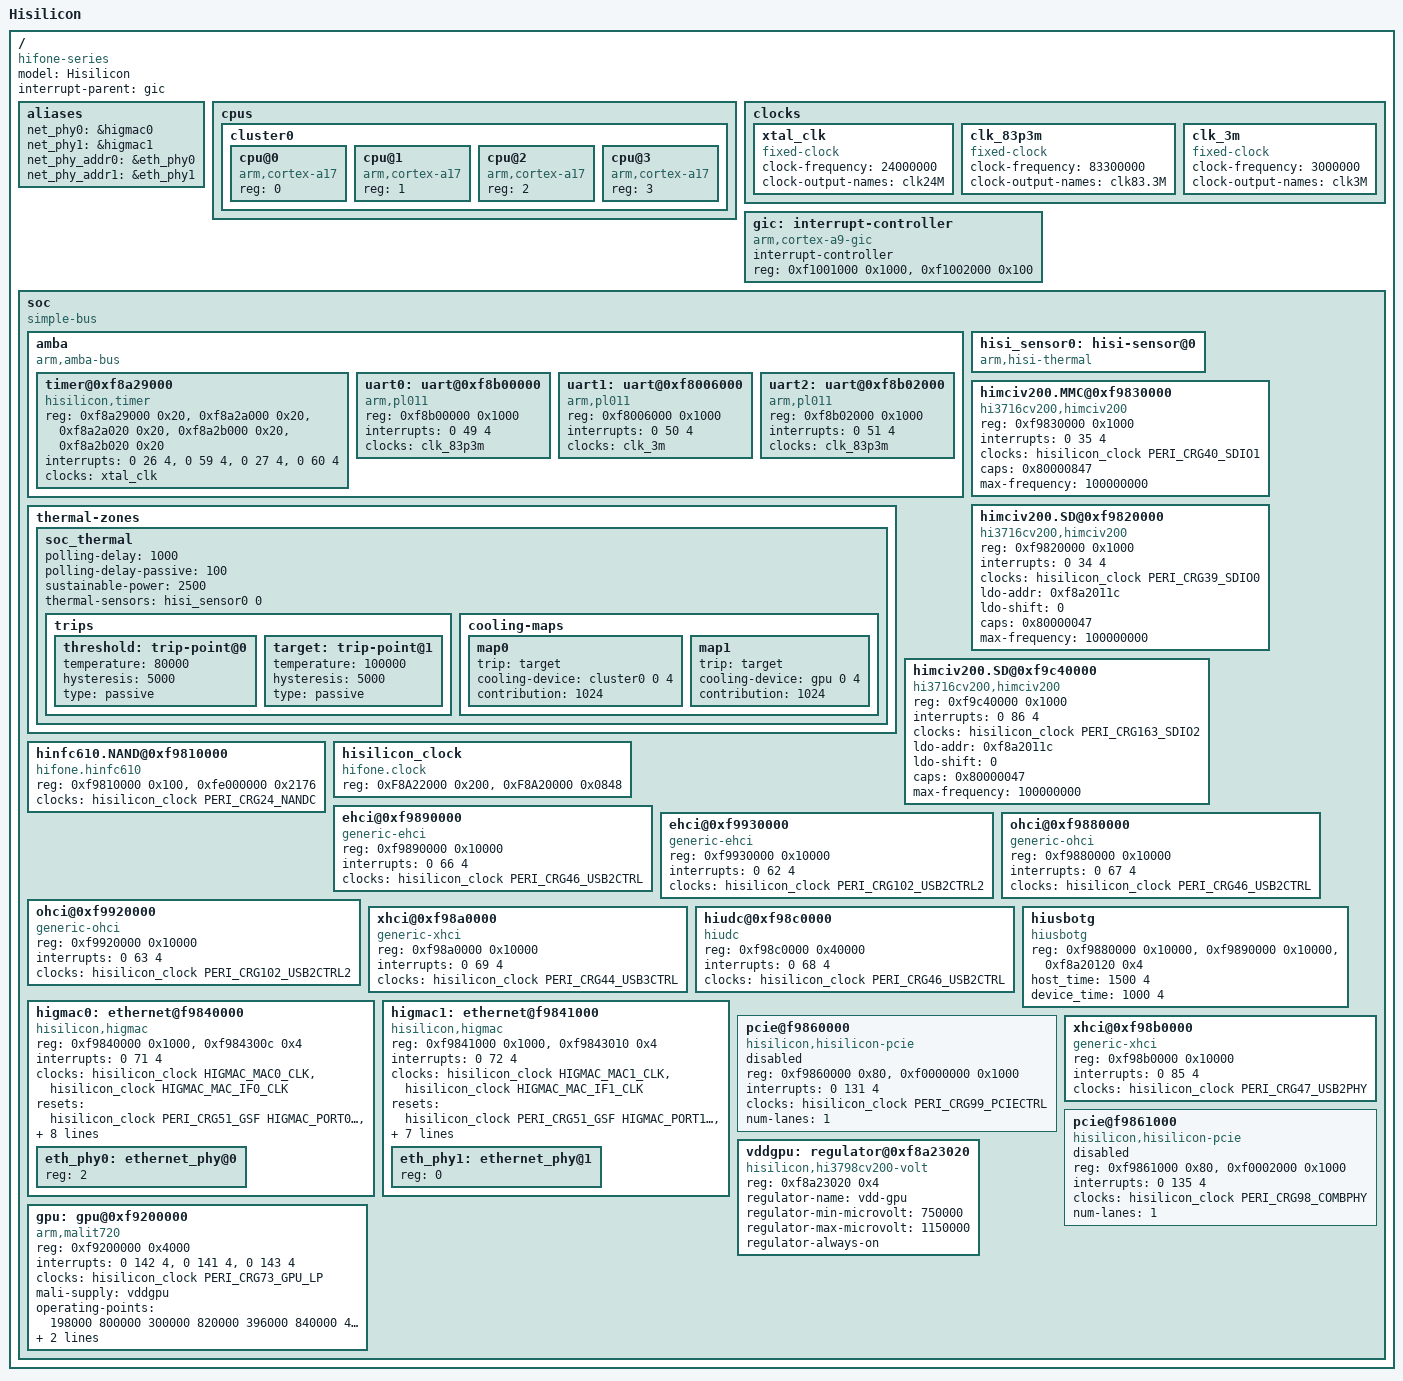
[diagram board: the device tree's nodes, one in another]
/dts-v1/;

#include <dt-bindings/clock/hifone-clock.h>

/ {
	model = "Hisilicon";
	compatible = "hifone-series";
	#address-cells = <1>;
	#size-cells = <1>;
	interrupt-parent = <&gic>;

	aliases {
		net_phy0 = &higmac0;
		net_phy1 = &higmac1;
		net_phy_addr0 = &eth_phy0;
		net_phy_addr1 = &eth_phy1;
	};

	cpus {
		cluster0: cluster0 {
			#address-cells = <1>;
			#size-cells = <0>;

			/* cooling options */
			#cooling-cells = <2>; /* min followed by max */

			cpu@0 {
				device_type = "cpu";
				compatible = "arm,cortex-a17";
				reg = <0>;
			};

			cpu@1 {
				device_type = "cpu";
				compatible = "arm,cortex-a17";
				reg = <1>;
			};

			cpu@2 {
				device_type = "cpu";
				compatible = "arm,cortex-a17";
				reg = <2>;
			};

			cpu@3 {
				device_type = "cpu";
				compatible = "arm,cortex-a17";
				reg = <3>;
			};
		}; /* cluster0 */
	}; /* cpus */

	clocks {
		xtal_clk: xtal_clk {
			compatible = "fixed-clock";
			#clock-cells = <0>;
			clock-frequency = <24000000>;
			clock-output-names = "clk24M";
		};

		clk_83p3m: clk_83p3m {
			compatible = "fixed-clock";
			#clock-cells = <0>;
			clock-frequency = <83300000>;
			clock-output-names = "clk83.3M";
		};

		clk_3m: clk_3m{
			compatible = "fixed-clock";
			#clock-cells = <0>;
			clock-frequency = <3000000>;
			clock-output-names = "clk3M";
		};
	};

	gic: interrupt-controller {
		compatible = "arm,cortex-a9-gic";
		#interrupt-cells = <3>;
		#address-cells = <0>;
		interrupt-controller;
		reg = <0xf1001000 0x1000>,
		      <0xf1002000 0x100>;
	};

	soc {
		#address-cells = <1>;
		#size-cells = <1>;
		compatible = "simple-bus";
		device_type = "soc";
		ranges = <0x0 0x0 0xffffffff>;

		amba {
			compatible = "arm,amba-bus";
			#address-cells = <1>;
			#size-cells = <1>;
			ranges;

			/*
			 * Used for clocksource and local timer
			 */
			timer@0xf8a29000 {
				compatible = "hisilicon,timer";
				reg = <0xf8a29000 0x20>, /* clocksource */
				      <0xf8a2a000 0x20>, /* local timer for each cpu */
				      <0xf8a2a020 0x20>,
				      <0xf8a2b000 0x20>,
				      <0xf8a2b020 0x20>;
				interrupts = <0 26 4>, /* irq of local timer */
					     <0 59 4>,
					     <0 27 4>,
					     <0 60 4>;
				clocks = <&xtal_clk>;
				clock-names = "apb_pclk";
			};

			uart0: uart@0xf8b00000 {
				compatible = "arm,pl011", "arm,primecell";
				reg = <0xf8b00000 0x1000>;
				interrupts = <0 49 4>;
				clocks = <&clk_83p3m>;
				clock-names = "apb_pclk";
			};

			uart1: uart@0xf8006000 {
				compatible = "arm,pl011", "arm,primecell";
				reg = <0xf8006000 0x1000>;
				interrupts = <0 50 4>;
				clocks = <&clk_3m>;
				clock-names = "apb_pclk";
			};

			uart2: uart@0xf8b02000 {
				compatible = "arm,pl011", "arm,primecell";
				reg = <0xf8b02000 0x1000>;
				interrupts = <0 51 4>;
				clocks = <&clk_83p3m>;
				clock-names = "apb_pclk";
			};
		};

		hisi_sensor0: hisi-sensor@0 {
			compatible = "arm,hisi-thermal";
			#thermal-sensor-cells = <1>;
		};

		thermal-zones {
			soc_thermal {
				polling-delay = <1000>;
				polling-delay-passive = <100>;
				sustainable-power = <2500>;

				thermal-sensors = <&hisi_sensor0 0>;

				trips {
					threshold: trip-point@0 {
						temperature = <80000>;
						hysteresis = <5000>;
						type = "passive";
					};
					target: trip-point@1 {
						temperature = <100000>;
						hysteresis = <5000>;
						type = "passive";
					};
				};

				cooling-maps {
					map0 {
					     trip = <&target>;
					     cooling-device = <&cluster0 0 4>;
					     contribution = <1024>;
					};
					map1 {
					    trip = <&target>;
					    cooling-device = <&gpu 0 4>;
					    contribution = <1024>;
					};
				};
			};
		};

		himciv200.MMC@0xf9830000 {
			compatible = "hi3716cv200,himciv200";
			reg = <0xf9830000 0x1000>;
			interrupts = <0 35 4>;

			clocks = <&hisilicon_clock PERI_CRG40_SDIO1>;
			clock-names = "clk";

			caps = <0x80000847>;
			max-frequency = <100000000>;
		};

		himciv200.SD@0xf9820000 {
			compatible = "hi3716cv200,himciv200";
			reg = <0xf9820000 0x1000>;
			interrupts = <0 34 4>;

			clocks = <&hisilicon_clock PERI_CRG39_SDIO0>;
			clock-names = "clk";

			ldo-addr  = <0xf8a2011c>;
			ldo-shift = <0>;

			caps = <0x80000047>;
			max-frequency = <100000000>;
		};

		himciv200.SD@0xf9c40000 {
			compatible = "hi3716cv200,himciv200";
			reg = <0xf9c40000 0x1000>;
			interrupts = <0 86 4>;

			clocks = <&hisilicon_clock PERI_CRG163_SDIO2>;
			clock-names = "clk";

			ldo-addr  = <0xf8a2011c>;
			ldo-shift = <0>;

			caps = <0x80000047>;
			max-frequency = <100000000>;
		};
		
		hinfc610.NAND@0xf9810000 {
			compatible = "hifone.hinfc610";
			reg = <0xf9810000 0x100>, <0xfe000000 0x2176>;

			clocks = <&hisilicon_clock PERI_CRG24_NANDC>;
			clock-names = "clk";
		};

		hisilicon_clock: hisilicon_clock {
			compatible = "hifone.clock","hisilicon,clock-reset";
			reg = <0xF8A22000 0x200>, <0xF8A20000 0x0848>;
			#clock-cells = <1>;
			#reset-cells = <2>;
		};

		ehci@0xf9890000 {
			compatible = "generic-ehci";
			reg = <0xf9890000 0x10000>;
			interrupts = <0 66 4>;

			clocks = <&hisilicon_clock PERI_CRG46_USB2CTRL>;
			clock-names = "clk";
		};

		ehci@0xf9930000 {
			compatible = "generic-ehci";
			reg = <0xf9930000 0x10000>;
			interrupts = <0 62 4>;

			clocks = <&hisilicon_clock PERI_CRG102_USB2CTRL2>;
			clock-names = "clk";
		};

		ohci@0xf9880000 {
			compatible = "generic-ohci";
			reg = <0xf9880000 0x10000>;
			interrupts = <0 67 4>;

			clocks = <&hisilicon_clock PERI_CRG46_USB2CTRL>;
			clock-names = "clk";
		};

		ohci@0xf9920000 {
			compatible = "generic-ohci";
			reg = <0xf9920000 0x10000>;
			interrupts = <0 63 4>;

			clocks = <&hisilicon_clock PERI_CRG102_USB2CTRL2>;
			clock-names = "clk";
		};

		xhci@0xf98a0000 {
			compatible = "generic-xhci";
			reg = <0xf98a0000 0x10000>;
			interrupts = <0 69 4>;

			clocks = <&hisilicon_clock PERI_CRG44_USB3CTRL>;
			clock-names = "clk";
		};

		hiudc@0xf98c0000 {
			compatible = "hiudc";
			reg = <0xf98c0000 0x40000>;
			interrupts = <0 68 4>;

			clocks = <&hisilicon_clock PERI_CRG46_USB2CTRL>;
			clock-names = "clk";
		};

		hiusbotg {
			compatible = "hiusbotg";
			reg = <0xf9880000 0x10000>,<0xf9890000 0x10000>,<0xf8a20120 0x4>;
			host_time = <1500 4>;
			device_time = <1000 4>;
		};

		higmac0: ethernet@f9840000 {
			compatible = "hisilicon,higmac";
			reg = <0xf9840000 0x1000>,<0xf984300c 0x4>;
			interrupts = <0 71 4>;

			clocks = <&hisilicon_clock HIGMAC_MAC0_CLK>,
					<&hisilicon_clock HIGMAC_MAC_IF0_CLK>;
			clock-names = "higmac_clk",
					"macif_clk";

			resets = <&hisilicon_clock PERI_CRG51_GSF HIGMAC_PORT0_RST_BIT>,
					<&hisilicon_clock PERI_CRG51_GSF HIGMAC_MACIF0_RST_BIT>,
					<&hisilicon_clock PERI_CRG51_GSF HIGMAC_PHY0_RST_BIT>;
			reset-names = "port_reset",
					"macif_reset",
					"phy_reset";

			#address-cells = <1>;
			#size-cells = <0>;

			mac-address = [00 00 00 00 00 00];

			phy-handle = <&eth_phy0>;
			phy-mode = "rgmii";
			internal-phy;
			phy-gpio-base = <0>;
			phy-gpio-bit = <0>;

			eth_phy0: ethernet_phy@0 {
				reg = <2>;
			};
		};
		higmac1: ethernet@f9841000 {
			compatible = "hisilicon,higmac";
			reg = <0xf9841000 0x1000>,<0xf9843010 0x4>;
			interrupts = <0 72 4>;

			clocks = <&hisilicon_clock HIGMAC_MAC1_CLK>,
					<&hisilicon_clock HIGMAC_MAC_IF1_CLK>;
			clock-names = "higmac_clk",
					"macif_clk";

			resets = <&hisilicon_clock PERI_CRG51_GSF HIGMAC_PORT1_RST_BIT>,
					<&hisilicon_clock PERI_CRG51_GSF HIGMAC_MACIF1_RST_BIT>,
					<&hisilicon_clock PERI_CRG51_GSF HIGMAC_PHY1_RST_BIT>;
			reset-names = "port_reset",
					"macif_reset",
					"phy_reset";

			#address-cells = <1>;
			#size-cells = <0>;

			mac-address = [00 00 00 00 00 00];

			phy-handle = <&eth_phy1>;
			phy-mode = "rgmii";
			phy-gpio-base = <0>;
			phy-gpio-bit = <0>;

			eth_phy1: ethernet_phy@1{
				reg = <0>;
			};
		};

		/* pcie@f9860000 and xhci@0xf98b0000, select 1 of 2 */
		pcie@f9860000 {
			compatible = "hisilicon,hisilicon-pcie", "snps,dw-pcie";
			reg = <0xf9860000 0x80>,<0xf0000000 0x1000>;
			interrupts = <0 131 4>;

			clocks = <&hisilicon_clock PERI_CRG99_PCIECTRL>;
			clock-names = "clk";

			#address-cells = <3>;
			#size-cells = <2>;
			device_type = "pci";
			ranges=<0x00000800 0 0xe2100000 0xe2100000 0 0x00100000
					0x81000000 0 0xe2000000 0xe2000000 0 0x00080000
					0x82000000 0 0xe0000000 0xe0000000 0 0x02000000>;
			num-lanes = <1>;
			status = "disabled";
		};

		xhci@0xf98b0000 {
			compatible = "generic-xhci";
			reg = <0xf98b0000 0x10000>;
			interrupts = <0 85 4>;

			clocks = <&hisilicon_clock PERI_CRG47_USB2PHY>;
			clock-names = "clk";
			status = "okay";
		};

		pcie@f9861000{
			compatible = "hisilicon,hisilicon-pcie", "snps,dw-pcie";
			reg = <0xf9861000 0x80>,<0xf0002000 0x1000>;
			interrupts = <0 135 4>;

			clocks = <&hisilicon_clock PERI_CRG98_COMBPHY>;
			clock-names = "clk";

			#address-cells = <3>;
			#size-cells = <2>;
			device_type = "pci";
			ranges=<0x00000800 0 0xea100000 0xea100000 0 0x00100000
					0x81000000 0 0xea000000 0xea000000 0 0x00080000
					0x82000000 0 0xe8000000 0xe8000000 0 0x02000000>;
			num-lanes = <1>;
			status = "disabled";
		};

		vddgpu: regulator@0xf8a23020 {
			compatible = "hisilicon,hi3798cv200-volt";
			reg = <0xf8a23020 0x4>;
			reg-names = "base-address";
			regulator-name = "vdd-gpu";
			regulator-min-microvolt = <750000>;
			regulator-max-microvolt = <1150000>;
			regulator-always-on;
		};

		gpu:gpu@0xf9200000 {
			compatible = "arm,malit720", "arm,mali", "arm,mali-midgard";
			reg = <0xf9200000 0x4000>;
			interrupts = <0 142 4>, <0 141 4>, <0 143 4>;
			interrupt-names = "JOB", "MMU", "GPU";

			#cooling-cells = <2>; /* min followed by max */

			clocks = <&hisilicon_clock PERI_CRG73_GPU_LP>;
			clock-names = "clk_mali";
			mali-supply = <&vddgpu>;
			operating-points = <
			198000 800000
			300000 820000
			396000 840000
			432000 860000
			498000 910000
			600000 980000>;

			cooling-min-state = <0>;
			cooling-max-state = <5>;

		};
	};
};
